# ipro7 register map
Vendor: intelpro; Series: BTBLE
CPU: ipro7, little endian
Registers are 32-bit, read-write, reset 0x0 unless marked. A register's access mark holds for its fields unless they carry their own. Offsets are from the block's base; [hi:lo] are bit positions; {n}, {i} and the like mark numbered series.

## PDS
Base 0x3008E000
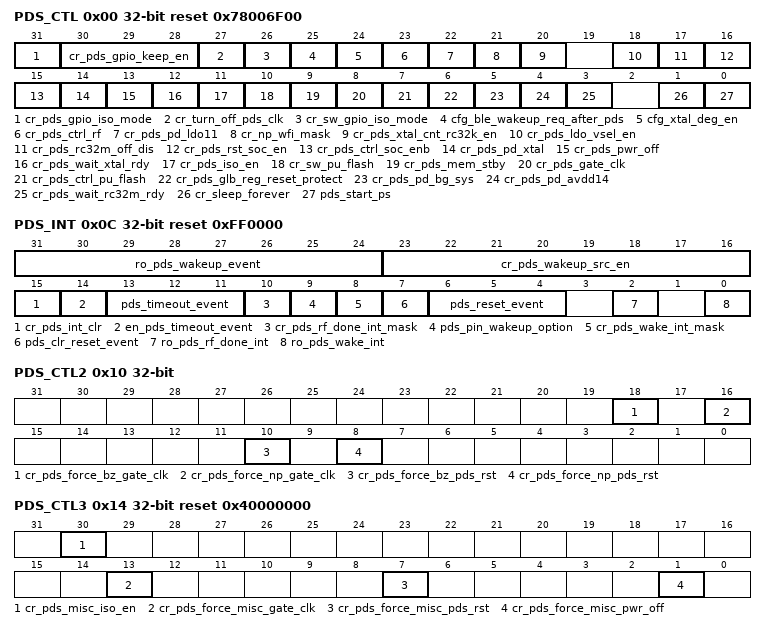
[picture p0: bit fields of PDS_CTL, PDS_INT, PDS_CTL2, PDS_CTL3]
0x00 PDS_CTL reset 0x78006F00
  [31] cr_pds_gpio_iso_mode — 1: HW Keep GPIO @ PDS7 0 : Clear this bit after PDS7 to release GPIO
  [30:28] cr_pds_gpio_keep_en — not supported
  [27] cr_turn_off_pds_clk — Turn off PDS Clock , Set this bit to 0 to active PDS
  [26] cr_sw_gpio_iso_mode — 1: SW force keep GPIO
  [25] cfg_ble_wakeup_req_after_pds — 1: PDS auto send ble_wakeup_req to sleep_timer when exit PDS
  [24] cfg_xtal_deg_en — 1: Enable Digital Deg
  [23] cr_pds_ctrl_rf — 0 : PDS don’t control RF on/off 1 : PDS control RF on/off
  [22] cr_pds_pd_ldo11 — 0 : power on ldo11 during PDS 1 : power down ldo11 during PDS
  [21] cr_np_wfi_mask — pds start condition mask np_wfi
  [20] cr_pds_xtal_cnt_rc32k_en — 1: HW Auto count RC32K to be XTAL Counter after PDS
  [18] cr_pds_ldo_vsel_en — PDS "SLEEP" control LDO voltage enable
  [17] cr_pds_rc32m_off_dis — 1 : RC32M always on @any state 0 : RC32M on/off controlled by PDS state
  [16] cr_pds_rst_soc_en — 0 : no pds_reset 1: pds_rst controlled by PDS
  [15] cr_pds_ctrl_soc_enb — 1 :pds_soc_enb controlled by PDS 0 :pds_soc_enb always active
  [14] cr_pds_pd_xtal — 0 : don’t_touch xtal during PDS 1 : xtal power down during PDS
  [13] cr_pds_pwr_off — 0 : don’t_touch Power during PDS 1 : Power off during PDS (each power domain can has its own control)
  [12] cr_pds_wait_xtal_rdy — 0 : Skip wait XTAL Ready before PDS Interrupt 1 : wait XTAL Ready during before PDS Interrupt
  [11] cr_pds_iso_en — 0 : don’t_touch Isolation during PDS (all power domain) 1 : Isolation during PDS (each power domain can has its own control)
  [10] cr_sw_pu_flash — if cr_pds_ctrl_pu_flash =0 or not in PDS31 state 0 : SW Turn Off Flash 1: SW Turn on Flash
  [9] cr_pds_mem_stby — 0 : don’t_touch mem_stby during PDS 1 : mem_stby during PDS (each power domain can has its own control)
  [8] cr_pds_gate_clk — 0 : don’t_touch clock gating during PDS (all power domain) 1 : gate clock during PDS (each pwr domain has its own control)
  [7] cr_pds_ctrl_pu_flash — 0 : don’'t touch Flash power during all PDS (Flash Power Always on) 1 : turn off Flash Power During PDS (same control with pds power off control)
  [6] cr_pds_glb_reg_reset_protect — 1: avoid glb_reg reset by any reset
  [5] cr_pds_pd_bg_sys — 0 : don’t_touch bg_sys during PDS 1 : power down bg_sys during PDS
  [4] cr_pds_pd_avdd14 — 0 : don’t_touch avdd14 during PDS 1 : power down avdd14 during PDS
  [3] cr_pds_wait_rc32m_rdy — 0 : Skip wait RC32M Ready before PDS Interrupt 1 : wait RC32M Ready during before PDS Interrupt
  [1] cr_sleep_forever
  [0] pds_start_ps wo — Enter PDS
0x0C PDS_INT reset 0xFF0000 (reset mask 0xFFC78A)
  [31:24] ro_pds_wakeup_event ro — Record Wakeup resason, and be clear by cr_pds_int_clr [31]: wakeup trigger by usb_wkup [30]: wakeup trigger by pds_watchdog_timeout event [29]: wakeup trigger by kys_int [28]: wakeup trigger by ble_slp_irq [27]: wakeup trigger by pds_gpio_int [26]: wakeup trigger by gpio_irq [25]: wakeup trigger by pds_kyd_wakeup [24]: wakeup trigger by hbn_irq_out[1:0]
  [23:16] cr_pds_wakeup_src_en — Mask PDS Wakeup Trigger [23]: enable wakeup trigger by usb_wkup [22] :enable wakeup trigger by pds_watchdog_timeout event [21]: enable wakeup trigger by kys_int [20]: enable wakeup trigger by ble_slp_irq [19]: enable wakeup trigger by pds_gpio_int [18]: enable wakeup trigger by gpio_irq [17]: enable wakeup trigger by pds_kyd_wakeup [16]: enable wakeup trigger by hbn_irq_out[1:0]
  [15] cr_pds_int_clr wo — pds interrupt & wakeup reason clear
  [14] en_pds_timeout_event
  [13:11] pds_timeout_event ro — [2] : ldo11soc_timeout event [1] : dcdc_timeout event [0] : pds_watchdog_timeout event
  [10] cr_pds_rf_done_int_mask — Mask pds rf done interrupt
  [9] pds_pin_wakeup_option — 1: Pin wakeup detect only at PDS 0 : No limited
  [8] cr_pds_wake_int_mask — Mask pds wakeup interrupt
  [7] pds_clr_reset_event wo — clear pds reset event
  [6:4] pds_reset_event ro — [2] : pds_rst_n (pds reset) [1]: pwr_rst_n (hbn power on reset) [0]: hreset_n (Bus Reset)
  [2] ro_pds_rf_done_int ro — pu_rf_done interrupt
  [0] ro_pds_wake_int ro — PDS Wakeup Interrupt
0x10 PDS_CTL2
  [18] cr_pds_force_bz_gate_clk — manual force BZ clock gated
  [16] cr_pds_force_np_gate_clk — manual force NP clock gated
  [10] cr_pds_force_bz_pds_rst — manual force BZ pds reset
  [8] cr_pds_force_np_pds_rst — manual force NP pds reset
0x14 PDS_CTL3 reset 0x40000000
  [30] cr_pds_misc_iso_en — 1 : make misc isolated at PDS Sleep state 0 : make misc isolated at PDS Sleep state
  [13] cr_pds_force_misc_gate_clk — manual force MISC gate_clk
  [7] cr_pds_force_misc_pds_rst — manual force MISC pds_rst
  [1] cr_pds_force_misc_pwr_off — manual force MISC pwr_off
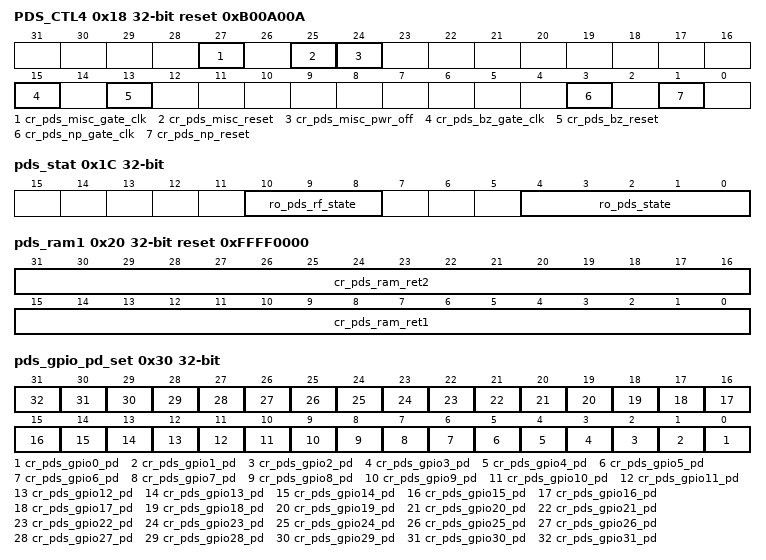
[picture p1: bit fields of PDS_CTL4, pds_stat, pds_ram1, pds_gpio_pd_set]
0x18 PDS_CTL4 reset 0xB00A00A
  [27] cr_pds_misc_gate_clk — 1 : make core_misc clock gated at PDS Sleep state 0 : make core_misc clocking at PDS Sleep state
  [25] cr_pds_misc_reset — 1 : make core_misc reset at PDS Sleep state 0 : make core_misc not reset at PDS Sleep state
  [24] cr_pds_misc_pwr_off — 1 : make core_misc Power off at PDS Sleep state 0 : make core_misc power on at PDS Sleep state
  [15] cr_pds_bz_gate_clk — 1 : make BZ clock gated at PDS Sleep state 0 : make BZ clocking at PDS Sleep state
  [13] cr_pds_bz_reset — 1 : make BZ reset at PDS Sleep state 0 : make BZ not reset at PDS Sleep state
  [3] cr_pds_np_gate_clk — 1 : make NP clock gated at PDS Sleep state 0 : make NP clocking at PDS Sleep state
  [1] cr_pds_np_reset — 1 : make NP reset at PDS Sleep state 0 : make NP not reset at PDS Sleep state
0x1C pds_stat (reset mask 0xFFFFF8E0)
  [10:8] ro_pds_rf_state ro, [4:0] ro_pds_state ro
0x20 pds_ram1 reset 0xFFFF0000
  [31:16] cr_pds_ram_ret2 — [7] : 128~144KB EM RET2 [4] : 64~80KB ocram RET2 [3] : 48~64KB ocram RET2 [2] : 32~48KB ocram RET2 [1] : 16~32KB ocram RET2 [0] : 0~16KB ocram RET2
  [15:0] cr_pds_ram_ret1 — [7] : 128~144KB EM RET1 [4] : 64~80KB ocram RET1 [3] : 48~64KB ocram RET1 [2] : 32~48KB ocram RET1 [1] : 16~32KB ocram RET1 [0] : 0~16KB ocram RET1
0x24 pds_ram2
  [15:0] cr_pds_ram_pgen — [7] : 128~144KB EM PGEN [4] : 64~80KB ocram PGEN [3] : 48~64KB ocram PGEN [2] : 32~48KB ocram PGEN [1] : 16~32KB ocram PGEN [0] : 0~16KB ocram PGEN
0x30 pds_gpio_pd_set
  [n] cr_pds_gpio{n}_pd (n=0..31) — PDS GPIO PD : GPIO{n}
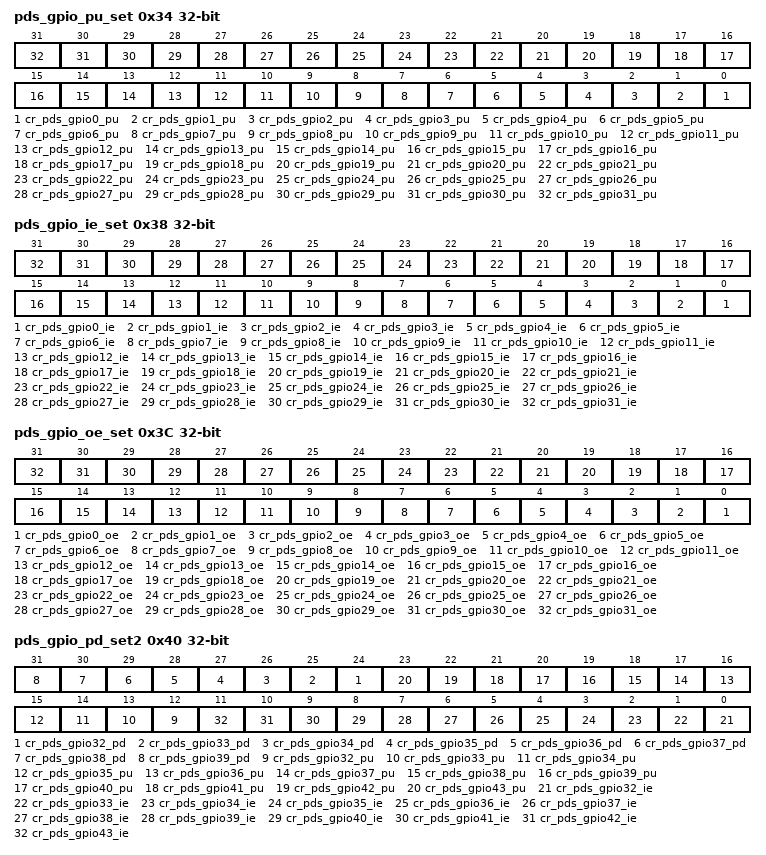
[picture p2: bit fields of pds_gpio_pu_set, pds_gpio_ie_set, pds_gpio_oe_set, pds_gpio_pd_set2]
0x34 pds_gpio_pu_set
  [n] cr_pds_gpio{n}_pu (n=0..31) — PDS GPIO PU : GPIO{n}
0x38 pds_gpio_ie_set
  [n] cr_pds_gpio{n}_ie (n=0..31) — PDS GPIO IE : GPIO{n}
0x3C pds_gpio_oe_set
  [n] cr_pds_gpio{n}_oe (n=0..31) — PDS GPIO OE : GPIO{n}
0x40 pds_gpio_pd_set2
  [n-8] cr_pds_gpio{n}_pd (n=32..39) — PDS GPIO PD : GPIO{n}
  [n-20] cr_pds_gpio{n}_pu (n=32..43) — PDS GPIO PU : GPIO{n}
  [n-32] cr_pds_gpio{n}_ie (n=32..43) — PDS GPIO IE : GPIO{n}
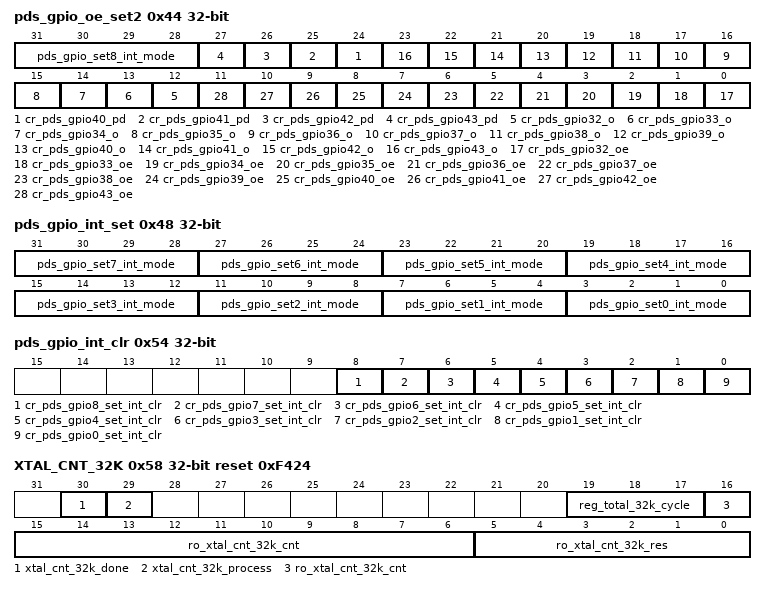
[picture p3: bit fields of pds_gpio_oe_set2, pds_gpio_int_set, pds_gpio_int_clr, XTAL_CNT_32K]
0x44 pds_gpio_oe_set2
  [31:28] pds_gpio_set8_int_mode — GPIO40~43 PDS Interrupt Mode 0000 : sync falling edge trigger 0001 : sync rising edge trigger 0010 : sync low level trigger 0011 : sync high level trigger 0011 : sync high level trigger 010x : sync rising or falling edge trigger 1000 : async falling edge trigger 1001 : async rising edge trigger 1010 : async low level trigger 1011 : async high level trigger
  [n-16] cr_pds_gpio{n}_pd (n=40..43) — PDS GPIO PD : GPIO{n}
  [n-20] cr_pds_gpio{n}_o (n=32..43) — PDS GPIO O : GPIO{n}
  [n-32] cr_pds_gpio{n}_oe (n=32..43) — PDS GPIO OE : GPIO{n}
0x48 pds_gpio_int_set
  [31:28] pds_gpio_set7_int_mode — GPIO36~39 PDS Interrupt Mode 0000 : sync falling edge trigger 0001 : sync rising edge trigger 0010 : sync low level trigger 0011 : sync high level trigger 0011 : sync high level trigger 010x : sync rising or falling edge trigger 1000 : async falling edge trigger 1001 : async rising edge trigger 1010 : async low level trigger 1011 : async high level trigger
  [4n+3:4n] pds_gpio_set{n}_int_mode (n=3..6) — GPIO{4n+8}~{4n+11} PDS Interrupt Mode 0000 : sync falling edge trigger 0001 : sync rising edge trigger 0010 : sync low level trigger 0011 : sync high level trigger 010x : sync rising or falling edge trigger 1000 : async falling edge trigger 1001 : async rising edge trigger 1010 : async low level trigger 1011 : async high level trigger
  [11:8] pds_gpio_set2_int_mode — GPIO8~9 PDS Interrupt Mode 0000 : sync falling edge trigger 0001 : sync rising edge trigger 0010 : sync low level trigger 0011 : sync high level trigger 010x : sync rising or falling edge trigger 1000 : async falling edge trigger 1001 : async rising edge trigger 1010 : async low level trigger 1011 : async high level trigger
  [7:4] pds_gpio_set1_int_mode — GPIO4~7 PDS Interrupt Mode 0000 : sync falling edge trigger 0001 : sync rising edge trigger 0010 : sync low level trigger 0011 : sync high level trigger 010x : sync rising or falling edge trigger 1000 : async falling edge trigger 1001 : async rising edge trigger 1010 : async low level trigger 1011 : async high level trigger
  [3:0] pds_gpio_set0_int_mode — GPIO0~3 PDS Interrupt Mode 0000 : sync falling edge trigger 0001 : sync rising edge trigger 0010 : sync low level trigger 0011 : sync high level trigger 010x : sync rising or falling edge trigger 1000 : async falling edge trigger 1001 : async rising edge trigger 1010 : async low level trigger 1011 : async high level trigger
0x4C pds_gpio_stat reset not defined
  [31:0] pds_gpio_int_stat ro — PDS GPIO Intrrupt Status (GPIO0~31) [31:10] GPIO41~GPIO20 [9:0] GPIO0~GPIO9
0x50 pds_gpio_int_mask reset 0xFFFFFFFF
  [31:0] cr_pds_gpio_int_mask — pds_gpio_int_mask [31:10] GPIO20~GPIO41 [9:0] GPIO0~GPIO9
0x54 pds_gpio_int_clr
  [8] cr_pds_gpio8_set_int_clr wo — pds_gpio_set7_int_clr (GPIO40~43)
  [7] cr_pds_gpio7_set_int_clr wo — pds_gpio_set7_int_clr (GPIO36~39)
  [6] cr_pds_gpio6_set_int_clr wo — pds_gpio_set6_int_clr (GPIO32~35)
  [5] cr_pds_gpio5_set_int_clr wo — pds_gpio_set5_int_clr (GPIO28~31)
  [4] cr_pds_gpio4_set_int_clr wo — pds_gpio_set4_int_clr(GPIO24~27)
  [3] cr_pds_gpio3_set_int_clr wo — pds_gpio_set3_int_clr (GPIO20~23)
  [2] cr_pds_gpio2_set_int_clr wo — pds_gpio_set2_int_clr (GPIO8~9)
  [1] cr_pds_gpio1_set_int_clr wo — pds_gpio_set1_int_clr (GPIO4~7)
  [0] cr_pds_gpio0_set_int_clr wo — pds_gpio_set0_int_clr (GPIO0~3)
0x58 XTAL_CNT_32K reset 0xF424 (reset mask 0x9FFE0000)
  [30] xtal_cnt_32k_done ro — also to IRQ[33]
  [29] xtal_cnt_32k_process ro
  [19:17] reg_total_32k_cycle — Average of 32K Cycle 4~7: 64 Cycle 3 : 32 Cycle 2 : 16 Cycle 1 : 8 Cycle 0 : 4 Cycle
  [16:6] ro_xtal_cnt_32k_cnt ro — Average 32K in XTAL CNT Cycle
  [5:0] ro_xtal_cnt_32k_res ro — Residue of XTAL Cycle Corresponding to reg_total_32_cycle xtal_cnt_32k_res in units of 1/64 XTAL Cycle
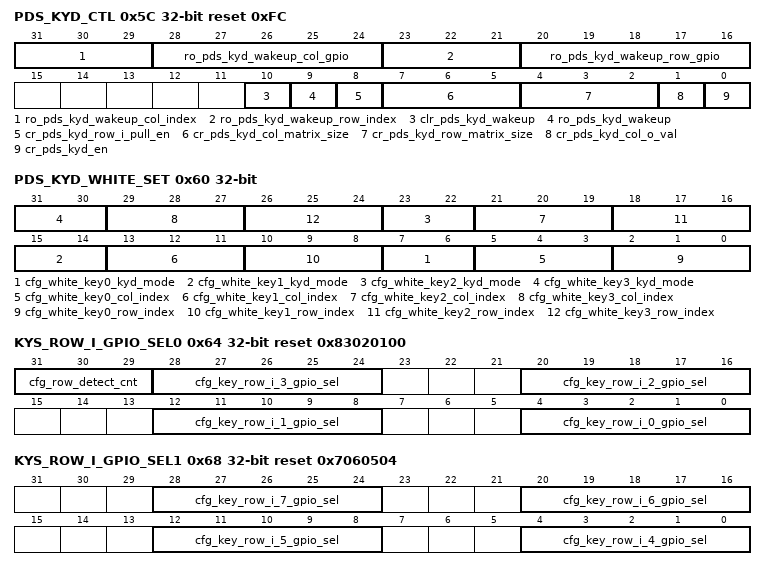
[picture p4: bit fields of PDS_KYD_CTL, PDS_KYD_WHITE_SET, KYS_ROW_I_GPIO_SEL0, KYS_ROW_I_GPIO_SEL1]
0x5C PDS_KYD_CTL reset 0xFC (reset mask 0xFDFF)
  [31:29] ro_pds_kyd_wakeup_col_index ro
  [28:24] ro_pds_kyd_wakeup_col_gpio ro
  [23:21] ro_pds_kyd_wakeup_row_index ro
  [20:16] ro_pds_kyd_wakeup_row_gpio ro
  [10] clr_pds_kyd_wakeup wo
  [9] ro_pds_kyd_wakeup ro
  [8] cr_pds_kyd_row_i_pull_en — 1: enable pullup or pulldown row_i depend on cr_pds_kyd_col_o_val HW auto PULLUP if cr_pds_kyd_col_o_val = 0 HW auto PULLDOWN if cr_pds_kyd_col_o_val = 1
  [7:5] cr_pds_kyd_col_matrix_size — 0: Define 1 COL 1: Define 2 COL 2: Define 3 COL 3: Define 4 COL 4: Define 5 COL 5: Define 6 COL 6: Define 7 COL 7: Define 8 COL
  [4:2] cr_pds_kyd_row_matrix_size — 0: Define 1 ROW 1: Define 2 ROW 2: Define 3 ROW 3: Define 4 ROW 4: Define 5 ROW 5: Define 6 ROW 6: Define 7 ROW 7: Define 8 ROW
  [1] cr_pds_kyd_col_o_val
  [0] cr_pds_kyd_en
0x60 PDS_KYD_WHITE_SET
  [8n+7:8n+6] cfg_white_key{n}_kyd_mode (n=0..3) — 00 :No White Key Function 01 : Invert Origital Detect Mode (for Pull button Detect) 1x : Mask Detect Mode (dont care Press or Pull button)
  [8n+5:8n+3] cfg_white_key{n}_col_index (n=0..3)
  [8n+2:8n] cfg_white_key{n}_row_index (n=0..3)
0x64 KYS_ROW_I_GPIO_SEL0 reset 0x83020100
  [31:29] cfg_row_detect_cnt — 0~3 : async detect 4~7 : sync detect
  [8n+4:8n] cfg_key_row_i_{n}_gpio_sel (n=0..3)
0x68 KYS_ROW_I_GPIO_SEL1 reset 0x7060504
  [8n-28:8n-32] cfg_key_row_i_{n}_gpio_sel (n=4..7)
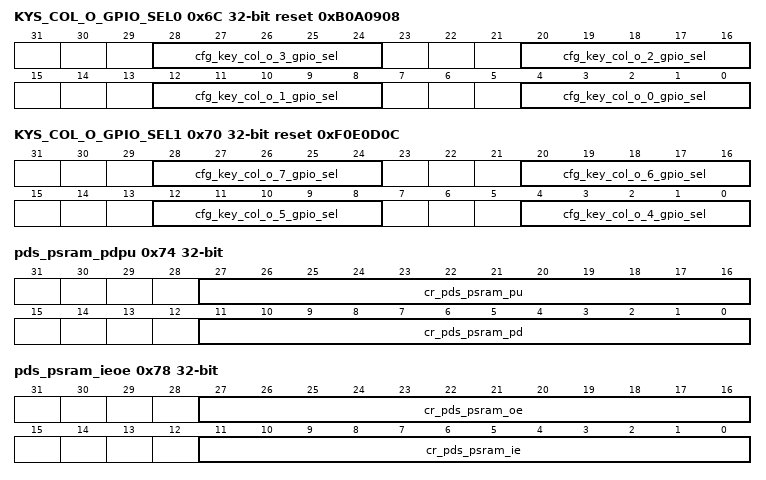
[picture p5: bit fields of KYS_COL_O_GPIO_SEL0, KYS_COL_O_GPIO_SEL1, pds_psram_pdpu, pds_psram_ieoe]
0x6C KYS_COL_O_GPIO_SEL0 reset 0xB0A0908
  [8n+4:8n] cfg_key_col_o_{n}_gpio_sel (n=0..3)
0x70 KYS_COL_O_GPIO_SEL1 reset 0xF0E0D0C
  [8n-28:8n-32] cfg_key_col_o_{n}_gpio_sel (n=4..7)
0x74 pds_psram_pdpu
  [27:16] cr_pds_psram_pu, [11:0] cr_pds_psram_pd
0x78 pds_psram_ieoe
  [27:16] cr_pds_psram_oe, [11:0] cr_pds_psram_ie
0x7C pds_psram_o
  [11:0] cr_pds_psram_o
0x80 pds_gpio_o
  [31:0] cr_pds_gpio_o_val
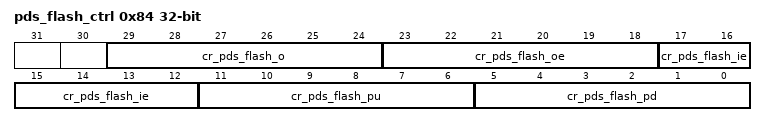
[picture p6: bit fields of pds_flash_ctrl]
0x84 pds_flash_ctrl
  [29:24] cr_pds_flash_o, [23:18] cr_pds_flash_oe, [17:12] cr_pds_flash_ie, [11:6] cr_pds_flash_pu, [5:0] cr_pds_flash_pd
0x88 CPU_CORE_CFG0 reset 0x10FE0000
  [31:9] mcu_rst_addr
